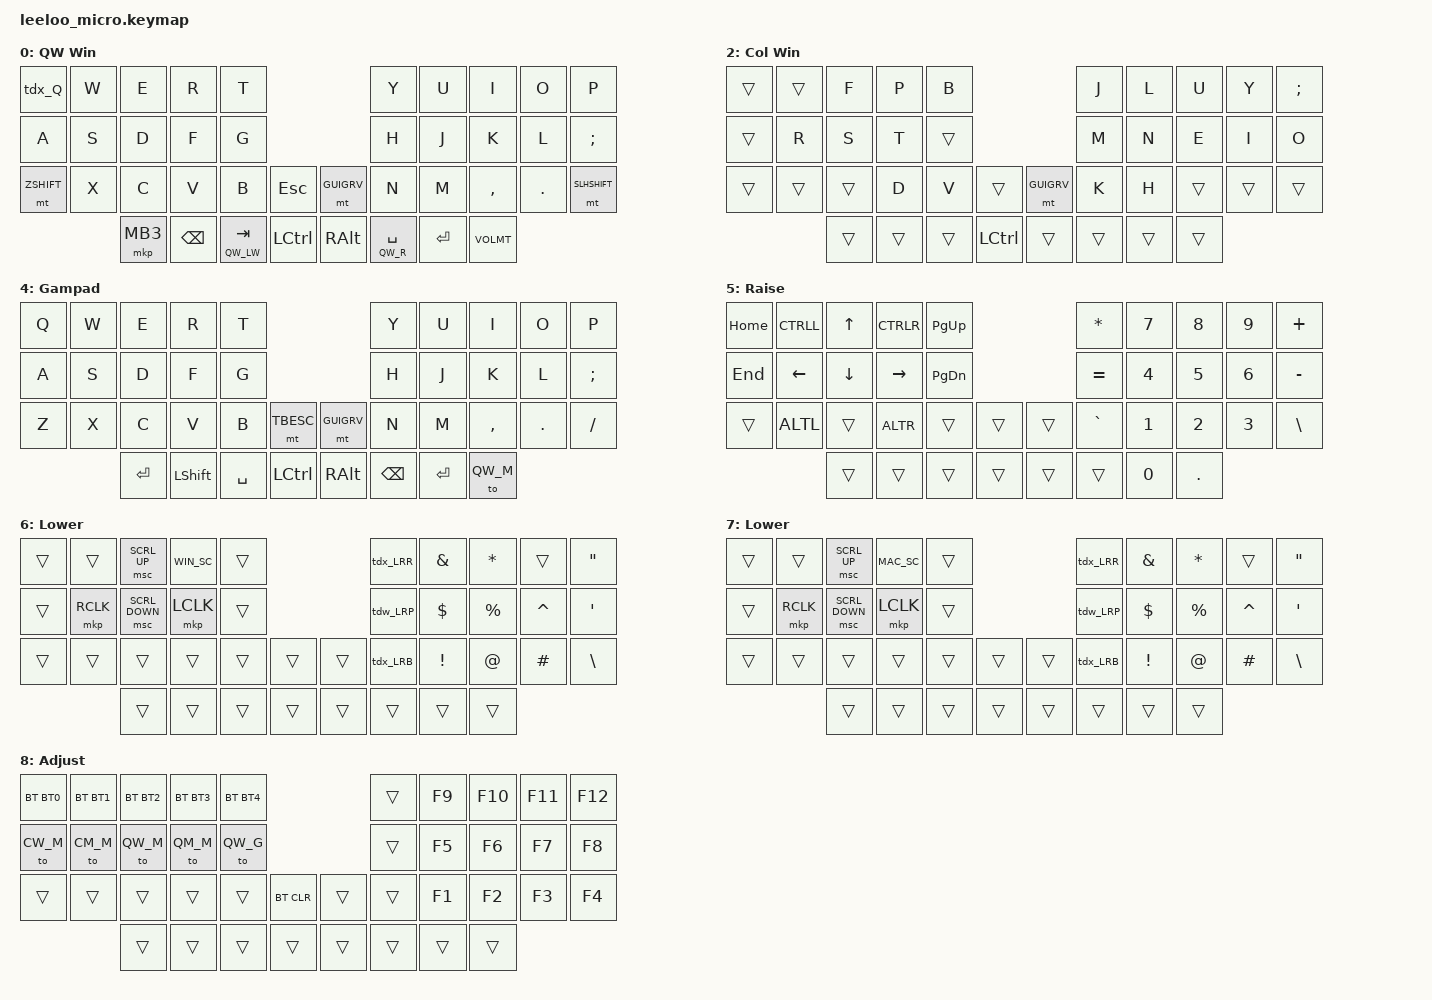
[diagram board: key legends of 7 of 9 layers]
/*
 * Copyright (c) 2022 The ZMK Contributors
 * SPDX-License-Identifier: MIT
 */

#include <behaviors.dtsi>
#include <dt-bindings/zmk/pointing.h>
#include <dt-bindings/zmk/outputs.h>
#include <dt-bindings/zmk/keys.h>
#include <dt-bindings/zmk/bt.h>
#include <dt-bindings/zmk/mouse.h>

// Layers
#define QW_M    0       // QWERTY - Windows
#define QM_M    1       // QWERTY - Mac
#define CW_M    2       // Colemak - Windows
#define CM_M    3       // Colemak - Mac
#define QW_G    4       // Gamepad - Windows
#define QW_R    5       // Raise
#define QW_LW   6       // Lower - Windows
#define QW_LM   7       // Lower - Mac
#define QW_A    8       // Adjust

// Short versions
#define GUIGRV      LGUI GRAVE
#define CTLGRV      LCTRL GRAVE
#define ZSHIFT      LSFT Z
#define SLHSHIFT    RSFT FSLH
#define SPTB        SPACE TAB
#define TBESC       TAB ESC
#define WIN_SC      LG(LS(S))
#define MAC_SC      LG(LC(LS(N4)))

#define enDSH_X     LA(MINUS)
#define emDSH_X     LS(LA(MINUS))

#define BT0         BT_SEL 0
#define BT1         BT_SEL 1
#define BT2         BT_SEL 2
#define BT3         BT_SEL 3
#define BT4         BT_SEL 4

#define VOLUP   C_VOL_UP
#define VOLDN   C_VOL_DN
#define VOLMT   C_MUTE
#define MPPAU   C_PLAY_PAUSE

#define CTRLL   LC(LEFT)
#define CTRLR   LC(RIGHT)
#define ALTL    LA(LEFT)
#define ALTR    LA(RIGHT)
#define LOCK    LG(L)

#define ZMK_POINTING_DEFAULT_SCRL_VAL 140

/* 
 * Assign the cs-gpios pin to 4.
 * Uncomment these next three lines if implementing nice!view Displays.
 */
&nice_view_spi {
    cs-gpios = <&pro_micro 4 GPIO_ACTIVE_HIGH>;
};

/ {
    conditional_layers {
        compatible = "zmk,conditional-layers";
        
        adjust_win_layer {
            if-layers = <QW_R QW_LW>;
            then-layer = <QW_A>;
        };
        
        adjust_mac_layer {
            if-layers = <QW_R QW_LM>;
            then-layer = <QW_A>;
        };
    };

    combos {
        compatible = "zmk,combos";

        combo_win_esc {
            timeout-ms = <50>;
            key-positions = <0 1>;
            layers = <QW_M>;
            bindings = <&kp ESC>;
        };
    };

    macros {
        enDSH_W: en_Dash {
            label = "enDSH_W";
            compatible = "zmk,behavior-macro";
            #binding-cells = <0>;
            wait-ms = <20>;
            tap-ms = <20>;
            bindings
                = <&macro_press   &kp LALT>
                , <&macro_tap     &kp KP_N0 &kp KP_N1 &kp KP_N5 &kp KP_N0>
                , <&macro_release &kp LALT>
                ;
        };

        emDSH_W: em_Dash {
            label = "emDSH_W";
            compatible = "zmk,behavior-macro";
            #binding-cells = <0>;
            wait-ms = <20>;
            tap-ms = <20>;
            bindings
                = <&macro_press   &kp LALT>
                , <&macro_tap     &kp KP_N0 &kp KP_N1 &kp KP_N5 &kp KP_N1>
                , <&macro_release &kp LALT>
                ;
        };
    };

    behaviors {
        tdw_Q: tap_dance_0 {
            compatible = "zmk,behavior-tap-dance";
            label = "WIN_QUIT";
            #binding-cells = <0>;
            tapping-term-ms = <200>;
            bindings = <&kp Q>, <&kp LA(F4)>;
        };

        tdx_Q: tap_dance_1 {
            compatible = "zmk,behavior-tap-dance";
            label = "OSX_QUIT";
            #binding-cells = <0>;
            tapping-term-ms = <200>;
            bindings = <&kp Q>, <&kp LG(Q)>;
        };

        tdw_LRP: tap_dance_2 {
            compatible = "zmk,behavior-tap-dance";
            label = "WIN_LRPAR";
            #binding-cells = <0>;
            tapping-term-ms = <200>;
            bindings = <&kp LPAR>, <&kp RPAR>;
        };

        tdx_LRB: tap_dance_3 {
            compatible = "zmk,behavior-tap-dance";
            label = "WIN_LRBKT";
            #binding-cells = <0>;
            tapping-term-ms = <200>;
            bindings = <&kp LBKT>, <&kp RBKT>;
        };

        tdx_LRR: tap_dance_4 {
            compatible = "zmk,behavior-tap-dance";
            label = "WIN_LRBRC";
            #binding-cells = <0>;
            tapping-term-ms = <200>;
            bindings = <&kp LBRC>, <&kp RBRC>;
        };

        tdx_LRA: tap_dance_5 {
            compatible = "zmk,behavior-tap-dance";
            label = "WIN_LRANG";
            #binding-cells = <0>;
            tapping-term-ms = <200>;
            bindings = <&kp LT>, <&kp GT>;
        };

        scroll_up_down: behavior_sensor_rotate_mouse_wheel_up_down {
	        compatible = "zmk,behavior-sensor-rotate";
	        #sensor-binding-cells = <0>;
            tap-ms = <20>;
            bindings = <&msc SCRL_UP>, <&msc SCRL_DOWN>;
};
    };

    keymap {
        compatible = "zmk,keymap";

        qw_layer {
            label = "QW Win";
            bindings = <
&tdx_Q     &kp W      &kp E      &kp R      &kp T                                &kp Y          &kp U      &kp I      &kp O      &kp P
&kp A      &kp S      &kp D      &kp F      &kp G                                &kp H          &kp J      &kp K      &kp L      &kp SEMI
&mt ZSHIFT &kp X      &kp C      &kp V      &kp B         &kp ESC    &mt GUIGRV  &kp N          &kp M      &kp COMMA  &kp DOT    &mt SLHSHIFT
                      &mkp MB3   &kp BSPC   &lt QW_LW TAB &kp LCTRL  &kp RALT    &lt QW_R SPACE &kp RET    &kp VOLMT
            >;

            sensor-bindings = <&scroll_up_down &inc_dec_kp C_VOL_UP C_VOL_DN>;
        };

        qm_layer {
            label = "QW Mac";
            bindings = <
&trans     &trans     &trans     &trans     &trans                                &trans     &trans     &trans     &trans     &trans
&trans     &trans     &trans     &trans     &trans                                &trans     &trans     &trans     &trans     &trans
&trans     &trans     &trans     &trans     &trans        &trans     &mt CTLGRV   &trans     &trans     &trans     &trans     &trans
                      &trans     &trans     &lt QW_LM TAB &kp LGUI   &trans       &trans     &trans
            >;

            sensor-bindings = <&scroll_up_down &inc_dec_kp C_VOL_UP C_VOL_DN>;
        };

        cw_layer {
            label = "Col Win";
            bindings = <
&trans     &trans     &kp F      &kp P      &kp B                                &kp J       &kp L      &kp U      &kp Y      &kp SEMI
&trans     &kp R      &kp S      &kp T      &trans                               &kp M       &kp N      &kp E      &kp I      &kp O
&trans     &trans     &trans     &kp D      &kp V       &trans      &mt GUIGRV   &kp K       &kp H      &trans     &trans     &trans
                      &trans     &trans     &trans      &kp LCTRL   &trans       &trans      &trans     &trans
            >;

            sensor-bindings = <&scroll_up_down &inc_dec_kp C_VOL_UP C_VOL_DN>;
        };

        cm_layer {
            label = "Col Mac";
            bindings = <
&trans     &trans     &kp F      &kp P      &kp B                                &kp J       &kp L      &kp U      &kp Y      &kp SEMI
&trans     &kp R      &kp S      &kp T      &trans                               &kp M       &kp N      &kp E      &kp I      &kp O
&trans     &trans     &trans     &kp D      &kp V       &trans     &mt CTLGRV    &kp K       &kp H      &trans     &trans     &trans
                      &trans     &trans     &trans      &kp LGUI   &trans        &trans     &trans
            >;

            sensor-bindings = <&scroll_up_down &inc_dec_kp C_VOL_UP C_VOL_DN>;
        };
                
        gamepad_layer {
            label = "Gampad";
            bindings = <
&kp Q      &kp W      &kp E    &kp R      &kp T                               &kp Y          &kp U      &kp I      &kp O      &kp P
&kp A      &kp S      &kp D    &kp F      &kp G                               &kp H          &kp J      &kp K      &kp L      &kp SEMI
&kp Z      &kp X      &kp C    &kp V      &kp B       &mt TBESC  &mt GUIGRV   &kp N          &kp M      &kp COMMA  &kp DOT    &kp FSLH
                      &kp RET  &kp LSHIFT &kp SPACE   &kp LCTRL  &kp RALT     &kp BSPC       &kp RET    &to QW_M
            >;

            sensor-bindings = <&inc_dec_kp UP DOWN &inc_dec_kp LEFT RIGHT>;
        };

        raise_layer {
            label = "Raise";
            bindings = <
&kp HOME   &kp CTRLL  &kp UP     &kp CTRLR  &kp PG_UP                        &kp ASTRK  &kp N7     &kp N8     &kp N9     &kp PLUS
&kp END    &kp LEFT   &kp DOWN   &kp RIGHT  &kp PG_DN                        &kp EQUAL  &kp N4     &kp N5     &kp N6     &kp MINUS
&trans     &kp ALTL   &trans     &kp ALTR   &trans     &trans     &trans     &kp GRAVE  &kp N1     &kp N2     &kp N3     &kp BSLH
                      &trans     &trans     &trans     &trans     &trans     &trans     &kp N0     &kp DOT
            >;

            sensor-bindings = <&scroll_up_down &inc_dec_kp C_VOL_UP C_VOL_DN>;
        };

        lower_win_layer {
            label = "Lower";
            bindings = <
&trans     &trans     &msc SCRL_UP   &kp WIN_SC &trans                           &tdx_LRR     &kp AMPS   &kp ASTRK  &trans      &kp DQT
&trans     &mkp RCLK  &msc SCRL_DOWN &mkp LCLK  &trans                           &tdw_LRP     &kp DLLR   &kp PRCNT  &kp CARET   &kp QUOT
&trans     &trans     &trans         &trans     &trans     &trans     &trans     &tdx_LRB     &kp EXCL   &kp AT     &kp HASH    &kp BSLH
                      &trans         &trans     &trans     &trans     &trans     &trans     &trans     &trans
            >;

            sensor-bindings = <&scroll_up_down &inc_dec_kp C_VOL_UP C_VOL_DN>;
        };

        lower_mac_layer {
            label = "Lower";
            bindings = <
&trans     &trans     &msc SCRL_UP   &kp MAC_SC &trans                           &tdx_LRR     &kp AMPS   &kp ASTRK  &trans      &kp DQT
&trans     &mkp RCLK  &msc SCRL_DOWN &mkp LCLK  &trans                           &tdw_LRP     &kp DLLR   &kp PRCNT  &kp CARET   &kp QUOT
&trans     &trans     &trans         &trans     &trans     &trans     &trans     &tdx_LRB     &kp EXCL   &kp AT     &kp HASH    &kp BSLH
                      &trans         &trans     &trans     &trans     &trans     &trans     &trans     &trans
            >;

            sensor-bindings = <&scroll_up_down &inc_dec_kp C_VOL_UP C_VOL_DN>;
        };

        adjust_layer {
            label = "Adjust";
            bindings = <

&bt BT0    &bt BT1    &bt BT2    &bt BT3    &bt BT4                          &trans     &kp F9     &kp F10    &kp F11    &kp F12
&to CW_M   &to CM_M   &to QW_M   &to QM_M   &to QW_G                         &trans     &kp F5     &kp F6     &kp F7     &kp F8
&trans     &trans     &trans     &trans     &trans     &bt BT_CLR &trans     &trans     &kp F1     &kp F2     &kp F3     &kp F4
                      &trans     &trans     &trans     &trans     &trans     &trans     &trans     &trans
            >;

            sensor-bindings = <&scroll_up_down &inc_dec_kp C_VOL_UP C_VOL_DN>;
        };

    };
};
